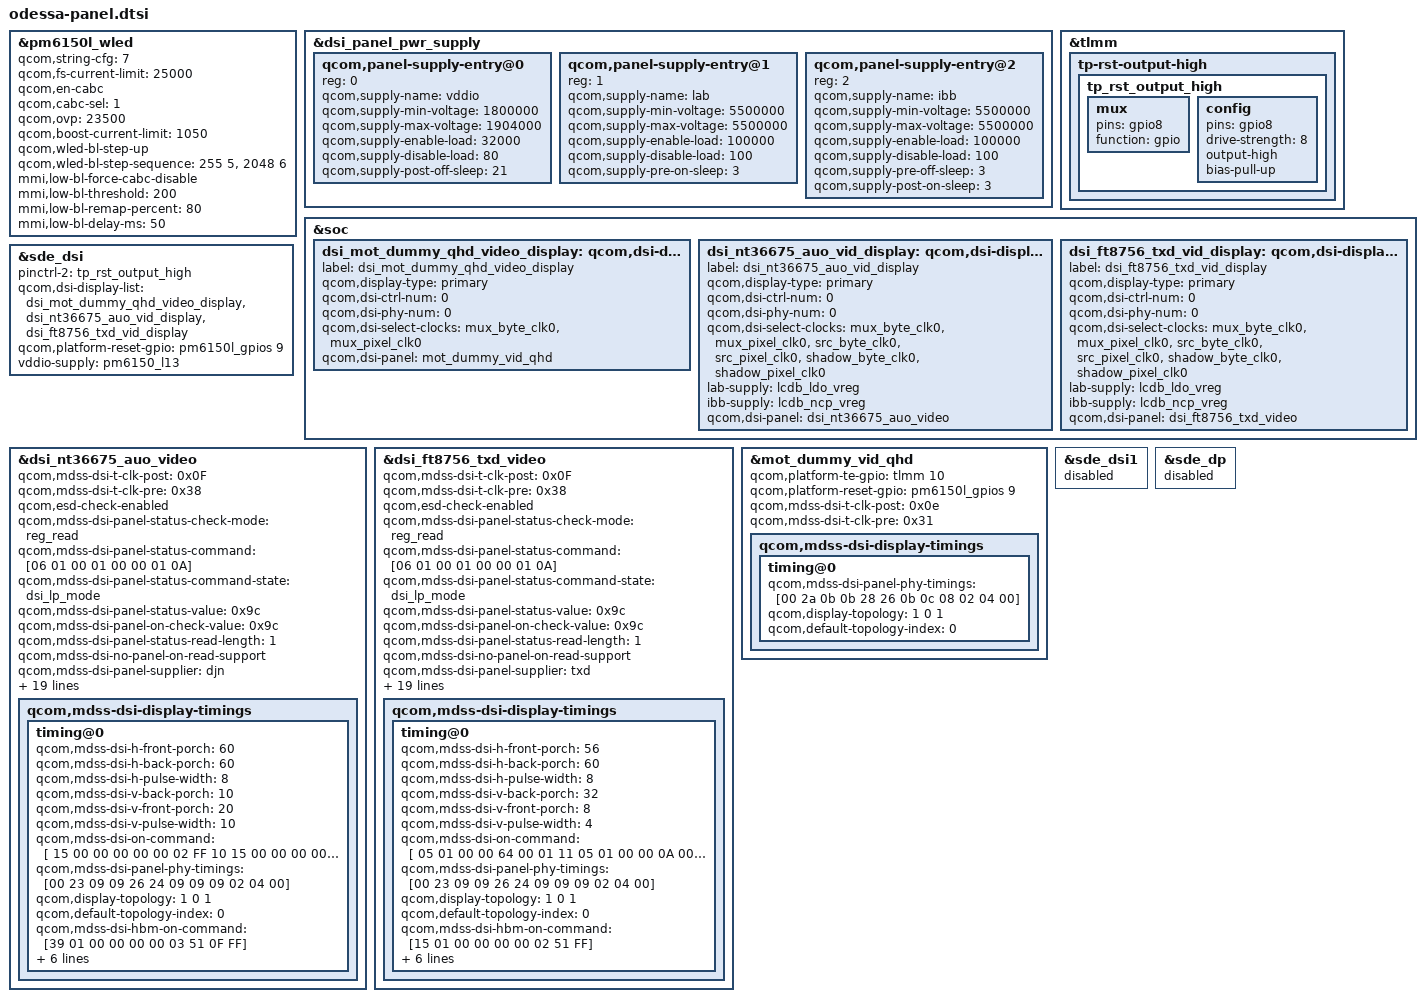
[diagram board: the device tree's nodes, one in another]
/*
 * Copyright (c) 2019, The Linux Foundation. All rights reserved.
 *
 * This program is free software; you can redistribute it and/or modify
 * it under the terms of the GNU General Public License version 2 and
 * only version 2 as published by the Free Software Foundation.
 *
 * This program is distributed in the hope that it will be useful,
 * but WITHOUT ANY WARRANTY; without even the implied warranty of
 * MERCHANTABILITY or FITNESS FOR A PARTICULAR PURPOSE.  See the
 * GNU General Public License for more details.
 */
#include "dsi-panel-mot-auo-nt36675-fhd-video.dtsi"
#include "dsi-panel-mot-txd-ft8756-fhd-video.dtsi"


&pm6150l_wled {
	qcom,string-cfg= <7>;
	status = "ok";
};

&dsi_panel_pwr_supply {
	qcom,panel-supply-entry@0 {
		reg = <0>;
		qcom,supply-name = "vddio";
		qcom,supply-min-voltage = <1800000>;
		qcom,supply-max-voltage = <1904000>;
		qcom,supply-enable-load = <32000>;
		qcom,supply-disable-load = <80>;
		qcom,supply-post-off-sleep= <21>;
	};

	qcom,panel-supply-entry@1 {
		reg = <1>;
		qcom,supply-name = "lab";
		qcom,supply-min-voltage = <5500000>;
		qcom,supply-max-voltage = <5500000>;
		qcom,supply-enable-load = <100000>;
		qcom,supply-disable-load = <100>;
		qcom,supply-pre-on-sleep = <3>;
	};

	qcom,panel-supply-entry@2 {
		reg = <2>;
		qcom,supply-name = "ibb";
		qcom,supply-min-voltage = <5500000>;
		qcom,supply-max-voltage = <5500000>;
		qcom,supply-enable-load = <100000>;
		qcom,supply-disable-load = <100>;
		qcom,supply-pre-off-sleep = <3>;
		qcom,supply-post-on-sleep = <3>;
	};
};

&tlmm {
	tp-rst-output-high {
		tp_rst_output_high: tp_rst_output_high {
			mux {
				pins = "gpio8";
				function = "gpio";
			};

			config {
				pins = "gpio8";
				drive-strength = <8>;
				output-high;
				bias-pull-up;
			};
		};
	};
};

&soc {
	dsi_mot_dummy_qhd_video_display: qcom,dsi-display@22 {
		label = "dsi_mot_dummy_qhd_video_display";
		qcom,display-type = "primary";

		qcom,dsi-ctrl-num = <0>;
		qcom,dsi-phy-num = <0>;
		qcom,dsi-select-clocks = "mux_byte_clk0", "mux_pixel_clk0";

		qcom,dsi-panel = <&mot_dummy_vid_qhd>;
	};
	dsi_nt36675_auo_vid_display: qcom,dsi-display@23 {
		label = "dsi_nt36675_auo_vid_display";
		qcom,display-type = "primary";

		qcom,dsi-ctrl-num = <0>;
		qcom,dsi-phy-num = <0>;
		qcom,dsi-select-clocks = "mux_byte_clk0", "mux_pixel_clk0",
			"src_byte_clk0", "src_pixel_clk0",
			"shadow_byte_clk0", "shadow_pixel_clk0";
		lab-supply = <&lcdb_ldo_vreg>;
		ibb-supply = <&lcdb_ncp_vreg>;
		qcom,dsi-panel = <&dsi_nt36675_auo_video>;
	};
	dsi_ft8756_txd_vid_display: qcom,dsi-display@24 {
		label = "dsi_ft8756_txd_vid_display";
		qcom,display-type = "primary";

		qcom,dsi-ctrl-num = <0>;
		qcom,dsi-phy-num = <0>;
		qcom,dsi-select-clocks = "mux_byte_clk0", "mux_pixel_clk0",
			"src_byte_clk0", "src_pixel_clk0",
			"shadow_byte_clk0", "shadow_pixel_clk0";
		lab-supply = <&lcdb_ldo_vreg>;
		ibb-supply = <&lcdb_ncp_vreg>;
		qcom,dsi-panel = <&dsi_ft8756_txd_video>;
	};
};

&sde_dsi {
	pinctrl-names = "panel_active", "panel_suspend", "tp-rst-output-high";
	pinctrl-2 = <&tp_rst_output_high>;
	qcom,dsi-display-list = <
		&dsi_mot_dummy_qhd_video_display
		&dsi_nt36675_auo_vid_display
		&dsi_ft8756_txd_vid_display>;
        /delete-property/ qcom,platform-te-gpio;
	/delete-property/ vddio-supply;
	qcom,platform-reset-gpio = <&pm6150l_gpios 9 0>;
	vddio-supply = <&pm6150_l13>;
};

&dsi_nt36675_auo_video {
	qcom,mdss-dsi-t-clk-post = <0x0F>;
	qcom,mdss-dsi-t-clk-pre = <0x38>;
	qcom,esd-check-enabled;
	qcom,mdss-dsi-panel-status-check-mode = "reg_read";
	qcom,mdss-dsi-panel-status-command = [06 01 00 01 00 00 01 0A];
	qcom,mdss-dsi-panel-status-command-state = "dsi_lp_mode";
	qcom,mdss-dsi-panel-status-value = <0x9c>;
	qcom,mdss-dsi-panel-on-check-value = <0x9c>;
	qcom,mdss-dsi-panel-status-read-length = <1>;
	qcom,mdss-dsi-no-panel-on-read-support;
	qcom,mdss-dsi-panel-supplier = "djn";
	qcom,tp_state_check_enable;
	qcom,mdss-dsi-panel-hdr-enabled;
	qcom,mdss-dsi-panel-hdr-color-primaries = <15115 15895 32830
				16770 15010 32385 7770 1830>;
	qcom,mdss-dsi-panel-peak-brightness = <4500000>;
	qcom,mdss-dsi-panel-blackness-level = <3000>;
	qcom,mdss-dsi-reset-sequence = <1 3>, <0 4>, <1 5>, <0 4>, <1 10>;
	qcom,mdss-pan-physical-width-dimension = <71>;
	qcom,mdss-pan-physical-height-dimension = <158>;
	qcom,mdss-dsi-display-timings {
		timing@0{
			qcom,mdss-dsi-h-front-porch = <60>;
			qcom,mdss-dsi-h-back-porch = <60>;
			qcom,mdss-dsi-h-pulse-width = <8>;
			qcom,mdss-dsi-v-back-porch = <10>;
			qcom,mdss-dsi-v-front-porch = <20>;
			qcom,mdss-dsi-v-pulse-width = <10>;
			qcom,mdss-dsi-on-command =
			[
				15 00 00 00 00 00 02 FF 10
				15 00 00 00 00 00 02 FB 01
				39 00 00 00 00 00 03 68 02 01
				39 00 00 00 00 00 03 51 0C CC
				15 00 00 00 00 00 02 53 2C
				15 00 00 00 00 00 02 55 01
				05 01 00 00 46 00 01 11
				05 01 00 00 28 00 01 29
			];
			qcom,mdss-dsi-panel-phy-timings = [00 23 09 09 26 24 09
				09 09 02 04 00];

			qcom,display-topology = <1 0 1>;
			qcom,default-topology-index = <0>;
			qcom,mdss-dsi-hbm-on-command = [39 01 00 00 00 00 03 51 0F FF];
			qcom,mdss-dsi-hbm-on-command-state =  "dsi_hs_mode";
			qcom,mdss-dsi-hbm-off-command = [39 01 00 00 00 00 03 51 0C CC];
			qcom,mdss-dsi-hbm-off-command-state =  "dsi_hs_mode";
		};
	};
};

&dsi_ft8756_txd_video {
	qcom,mdss-dsi-t-clk-post = <0x0F>;
	qcom,mdss-dsi-t-clk-pre = <0x38>;
	qcom,esd-check-enabled;
	qcom,mdss-dsi-panel-status-check-mode = "reg_read";
	qcom,mdss-dsi-panel-status-command = [06 01 00 01 00 00 01 0A];
	qcom,mdss-dsi-panel-status-command-state = "dsi_lp_mode";
	qcom,mdss-dsi-panel-status-value = <0x9c>;
	qcom,mdss-dsi-panel-on-check-value = <0x9c>;
	qcom,mdss-dsi-panel-status-read-length = <1>;
	qcom,mdss-dsi-no-panel-on-read-support;
	qcom,mdss-dsi-panel-supplier = "txd";
	qcom,mdss-dsi-tprst-output-high-resume;
	qcom,tp_state_check_enable;
	qcom,mdss-dsi-panel-hdr-enabled;
	qcom,mdss-dsi-panel-hdr-color-primaries = <15115 15895 32830
				16770 15010 32385 7770 1830>;
	qcom,mdss-dsi-panel-peak-brightness = <4500000>;
	qcom,mdss-dsi-panel-blackness-level = <3000>;
	qcom,mdss-dsi-reset-sequence = <1 4>, <0 1>, <1 12>;
	qcom,mdss-pan-physical-width-dimension = <71>;
	qcom,mdss-pan-physical-height-dimension = <158>;
	qcom,mdss-dsi-display-timings {
		timing@0{
			qcom,mdss-dsi-h-front-porch = <56>;
			qcom,mdss-dsi-h-back-porch = <60>;
			qcom,mdss-dsi-h-pulse-width = <8>;
			qcom,mdss-dsi-v-back-porch = <32>;
			qcom,mdss-dsi-v-front-porch = <8>;
			qcom,mdss-dsi-v-pulse-width = <4>;
			qcom,mdss-dsi-on-command =
			[
				05 01 00 00 64 00 01 11
				05 01 00 00 0A 00 01 29
				15 00 00 00 00 00 02 51 CC
				15 00 00 00 00 00 02 53 2C
				15 01 00 00 00 00 02 55 01
			];
			qcom,mdss-dsi-panel-phy-timings = [00 23 09 09 26 24 09
				09 09 02 04 00];

			qcom,display-topology = <1 0 1>;
			qcom,default-topology-index = <0>;
			qcom,mdss-dsi-hbm-on-command = [15 01 00 00 00 00 02 51 FF];
			qcom,mdss-dsi-hbm-on-command-state =  "dsi_hs_mode";
			qcom,mdss-dsi-hbm-off-command = [15 01 00 00 00 00 02 51 CC];
			qcom,mdss-dsi-hbm-off-command-state =  "dsi_hs_mode";
		};
	};
};

&dsi_nt36675_auo_video {
	qcom,mdss-dsi-bl-pmic-control-type = "bl_ctrl_wled";
	qcom,mdss-dsi-bl-min-level = <27>;
	qcom,mdss-dsi-bl-max-level = <4095>;
	qcom,mdss-dsi-bl-default-level = <2047>;
	qcom,mdss-brightness-max-level = <4095>;
	qcom,platform-reset-gpio = <&pm6150l_gpios 9 0>;
	qcom,panel-supply-entries = <&dsi_panel_pwr_supply>;
};

&dsi_ft8756_txd_video {
	qcom,mdss-dsi-bl-pmic-control-type = "bl_ctrl_wled";
	qcom,mdss-dsi-bl-min-level = <27>;
	qcom,mdss-dsi-bl-max-level = <4095>;
	qcom,mdss-dsi-bl-default-level = <2047>;
	qcom,mdss-brightness-max-level = <4095>;
	qcom,platform-reset-gpio = <&pm6150l_gpios 9 0>;
	qcom,panel-supply-entries = <&dsi_panel_pwr_supply>;
};

&mot_dummy_vid_qhd {
	qcom,platform-te-gpio = <&tlmm 10 0>;
	qcom,platform-reset-gpio = <&pm6150l_gpios 9 0>;

	qcom,mdss-dsi-t-clk-post = <0x0e>;
	qcom,mdss-dsi-t-clk-pre = <0x31>;
	qcom,mdss-dsi-display-timings {
		timing@0{
			qcom,mdss-dsi-panel-phy-timings = [00 2a 0b 0b 28 26 0b
				0c 08 02 04 00];

			qcom,display-topology = <1 0 1>;
			qcom,default-topology-index = <0>;
		};
	};
};

&pm6150l_wled {
	qcom,fs-current-limit = <25000>;
	qcom,en-cabc;
	qcom,cabc-sel = <1>;
	qcom,ovp = <23500>;
	qcom,boost-current-limit = <1050>;
	qcom,wled-bl-step-up;
	qcom,wled-bl-step-sequence = <255 5>, <2048 6>;

	mmi,low-bl-force-cabc-disable;
	mmi,low-bl-threshold = <200>;
	mmi,low-bl-remap-percent = <80>;
	mmi,low-bl-delay-ms = <50>;
};

&sde_dsi1 {
	status = "disable";
};

&sde_dp {
	status = "disable";
};

